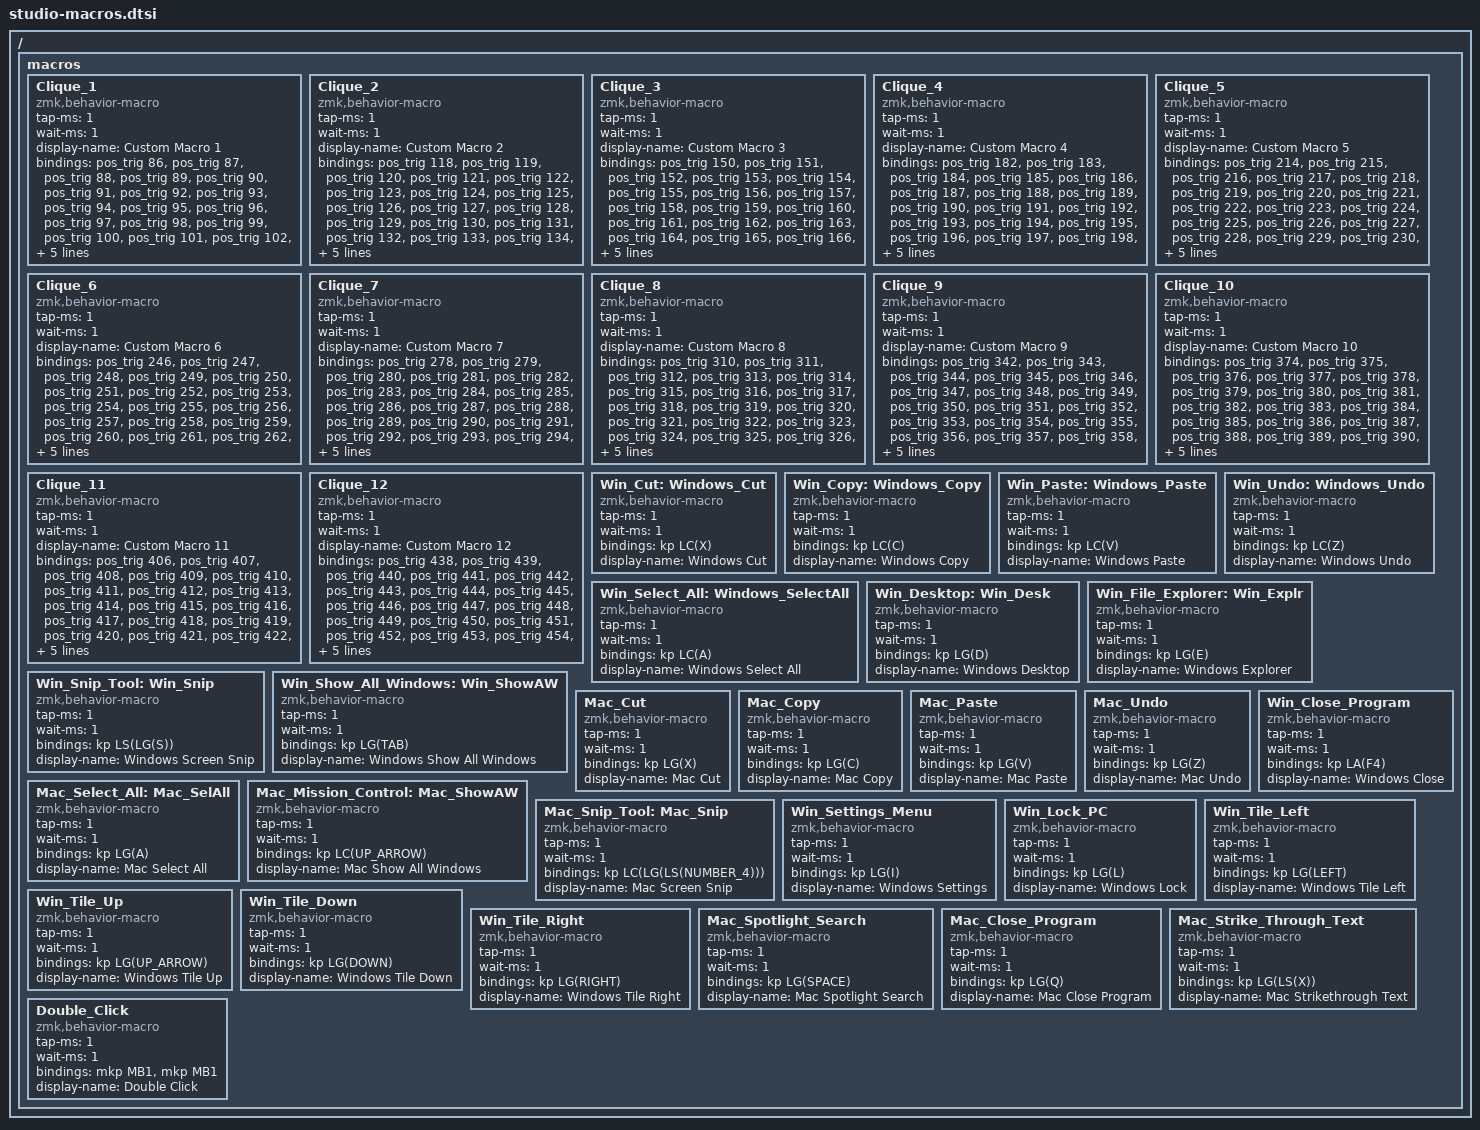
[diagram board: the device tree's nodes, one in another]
#include <dt-bindings/zmk/backlight.h>
#include <dt-bindings/zmk/bt.h>
#include <dt-bindings/zmk/keys.h>
#include <dt-bindings/zmk/pointing.h>
#include <dt-bindings/zmk/outputs.h>
#include <behaviors/position_trigger.dtsi>


/ {
    macros {
        Clique_1: Clique_1{
            compatible = "zmk,behavior-macro";
            #binding-cells = <0>;
            tap-ms = <1>;
            wait-ms = <1>;
            display-name = "Custom Macro 1";
            bindings = <&pos_trig 86 &pos_trig 87 &pos_trig 88 &pos_trig 89 &pos_trig 90 &pos_trig 91 &pos_trig 92 &pos_trig 93 &pos_trig 94 &pos_trig 95 &pos_trig 96 &pos_trig 97 &pos_trig 98 &pos_trig 99 &pos_trig 100 &pos_trig 101 &pos_trig 102 &pos_trig 103 &pos_trig 104 &pos_trig 105 &pos_trig 106 &pos_trig 107 &pos_trig 108 &pos_trig 109 &pos_trig 110 &pos_trig 111 &pos_trig 112 &pos_trig 113 &pos_trig 114 &pos_trig 115 &pos_trig 116 &pos_trig 117 >;
        };
        Clique_2: Clique_2{
            compatible = "zmk,behavior-macro";
            #binding-cells = <0>;
            tap-ms = <1>;
            wait-ms = <1>;
            display-name = "Custom Macro 2";
            bindings = <&pos_trig 118 &pos_trig 119 &pos_trig 120 &pos_trig 121 &pos_trig 122 &pos_trig 123 &pos_trig 124 &pos_trig 125 &pos_trig 126 &pos_trig 127 &pos_trig 128 &pos_trig 129 &pos_trig 130 &pos_trig 131 &pos_trig 132 &pos_trig 133 &pos_trig 134 &pos_trig 135 &pos_trig 136 &pos_trig 137 &pos_trig 138 &pos_trig 139 &pos_trig 140 &pos_trig 141 &pos_trig 142 &pos_trig 143 &pos_trig 144 &pos_trig 145 &pos_trig 146 &pos_trig 147 &pos_trig 148 &pos_trig 149 >;
        };
        Clique_3: Clique_3{
            compatible = "zmk,behavior-macro";
            #binding-cells = <0>;
            tap-ms = <1>;
            wait-ms = <1>;
            display-name = "Custom Macro 3";
            bindings = <&pos_trig 150 &pos_trig 151 &pos_trig 152 &pos_trig 153 &pos_trig 154 &pos_trig 155 &pos_trig 156 &pos_trig 157 &pos_trig 158 &pos_trig 159 &pos_trig 160 &pos_trig 161 &pos_trig 162 &pos_trig 163 &pos_trig 164 &pos_trig 165 &pos_trig 166 &pos_trig 167 &pos_trig 168 &pos_trig 169 &pos_trig 170 &pos_trig 171 &pos_trig 172 &pos_trig 173 &pos_trig 174 &pos_trig 175 &pos_trig 176 &pos_trig 177 &pos_trig 178 &pos_trig 179 &pos_trig 180 &pos_trig 181 >;
        };
        Clique_4: Clique_4{
            compatible = "zmk,behavior-macro";
            #binding-cells = <0>;
            tap-ms = <1>;
            wait-ms = <1>;
            display-name = "Custom Macro 4";
            bindings = <&pos_trig 182 &pos_trig 183 &pos_trig 184 &pos_trig 185 &pos_trig 186 &pos_trig 187 &pos_trig 188 &pos_trig 189 &pos_trig 190 &pos_trig 191 &pos_trig 192 &pos_trig 193 &pos_trig 194 &pos_trig 195 &pos_trig 196 &pos_trig 197 &pos_trig 198 &pos_trig 199 &pos_trig 200 &pos_trig 201 &pos_trig 202 &pos_trig 203 &pos_trig 204 &pos_trig 205 &pos_trig 206 &pos_trig 207 &pos_trig 208 &pos_trig 209 &pos_trig 210 &pos_trig 211 &pos_trig 212 &pos_trig 213 >;
        };
        Clique_5: Clique_5{
            compatible = "zmk,behavior-macro";
            #binding-cells = <0>;
            tap-ms = <1>;
            wait-ms = <1>;
            display-name = "Custom Macro 5";
            bindings = <&pos_trig 214 &pos_trig 215 &pos_trig 216 &pos_trig 217 &pos_trig 218 &pos_trig 219 &pos_trig 220 &pos_trig 221 &pos_trig 222 &pos_trig 223 &pos_trig 224 &pos_trig 225 &pos_trig 226 &pos_trig 227 &pos_trig 228 &pos_trig 229 &pos_trig 230 &pos_trig 231 &pos_trig 232 &pos_trig 233 &pos_trig 234 &pos_trig 235 &pos_trig 236 &pos_trig 237 &pos_trig 238 &pos_trig 239 &pos_trig 240 &pos_trig 241 &pos_trig 242 &pos_trig 243 &pos_trig 244 &pos_trig 245 >;
        };
        Clique_6: Clique_6{
            compatible = "zmk,behavior-macro";
            #binding-cells = <0>;
            tap-ms = <1>;
            wait-ms = <1>;
            display-name = "Custom Macro 6";
            bindings = <&pos_trig 246 &pos_trig 247 &pos_trig 248 &pos_trig 249 &pos_trig 250 &pos_trig 251 &pos_trig 252 &pos_trig 253 &pos_trig 254 &pos_trig 255 &pos_trig 256 &pos_trig 257 &pos_trig 258 &pos_trig 259 &pos_trig 260 &pos_trig 261 &pos_trig 262 &pos_trig 263 &pos_trig 264 &pos_trig 265 &pos_trig 266 &pos_trig 267 &pos_trig 268 &pos_trig 269 &pos_trig 270 &pos_trig 271 &pos_trig 272 &pos_trig 273 &pos_trig 274 &pos_trig 275 &pos_trig 276 &pos_trig 277 >;
        };
        Clique_7: Clique_7{
            compatible = "zmk,behavior-macro";
            #binding-cells = <0>;
            tap-ms = <1>;
            wait-ms = <1>;
            display-name = "Custom Macro 7";
            bindings = <&pos_trig 278 &pos_trig 279 &pos_trig 280 &pos_trig 281 &pos_trig 282 &pos_trig 283 &pos_trig 284 &pos_trig 285 &pos_trig 286 &pos_trig 287 &pos_trig 288 &pos_trig 289 &pos_trig 290 &pos_trig 291 &pos_trig 292 &pos_trig 293 &pos_trig 294 &pos_trig 295 &pos_trig 296 &pos_trig 297 &pos_trig 298 &pos_trig 299 &pos_trig 300 &pos_trig 301 &pos_trig 302 &pos_trig 303 &pos_trig 304 &pos_trig 305 &pos_trig 306 &pos_trig 307 &pos_trig 308 &pos_trig 309 >;
        };
        Clique_8: Clique_8{
            compatible = "zmk,behavior-macro";
            #binding-cells = <0>;
            tap-ms = <1>;
            wait-ms = <1>;
            display-name = "Custom Macro 8";
            bindings = <&pos_trig 310 &pos_trig 311 &pos_trig 312 &pos_trig 313 &pos_trig 314 &pos_trig 315 &pos_trig 316 &pos_trig 317 &pos_trig 318 &pos_trig 319 &pos_trig 320 &pos_trig 321 &pos_trig 322 &pos_trig 323 &pos_trig 324 &pos_trig 325 &pos_trig 326 &pos_trig 327 &pos_trig 328 &pos_trig 329 &pos_trig 330 &pos_trig 331 &pos_trig 332 &pos_trig 333 &pos_trig 334 &pos_trig 335 &pos_trig 336 &pos_trig 337 &pos_trig 338 &pos_trig 339 &pos_trig 340 &pos_trig 341 >;
        };
        Clique_9: Clique_9{
            compatible = "zmk,behavior-macro";
            #binding-cells = <0>;
            tap-ms = <1>;
            wait-ms = <1>;
            display-name = "Custom Macro 9";
            bindings = <&pos_trig 342 &pos_trig 343 &pos_trig 344 &pos_trig 345 &pos_trig 346 &pos_trig 347 &pos_trig 348 &pos_trig 349 &pos_trig 350 &pos_trig 351 &pos_trig 352 &pos_trig 353 &pos_trig 354 &pos_trig 355 &pos_trig 356 &pos_trig 357 &pos_trig 358 &pos_trig 359 &pos_trig 360 &pos_trig 361 &pos_trig 362 &pos_trig 363 &pos_trig 364 &pos_trig 365 &pos_trig 366 &pos_trig 367 &pos_trig 368 &pos_trig 369 &pos_trig 370 &pos_trig 371 &pos_trig 372 &pos_trig 373 >;
        };
        Clique_10: Clique_10{
            compatible = "zmk,behavior-macro";
            #binding-cells = <0>;
            tap-ms = <1>;
            wait-ms = <1>;
            display-name = "Custom Macro 10";
            bindings = <&pos_trig 374 &pos_trig 375 &pos_trig 376 &pos_trig 377 &pos_trig 378 &pos_trig 379 &pos_trig 380 &pos_trig 381 &pos_trig 382 &pos_trig 383 &pos_trig 384 &pos_trig 385 &pos_trig 386 &pos_trig 387 &pos_trig 388 &pos_trig 389 &pos_trig 390 &pos_trig 391 &pos_trig 392 &pos_trig 393 &pos_trig 394 &pos_trig 395 &pos_trig 396 &pos_trig 397 &pos_trig 398 &pos_trig 399 &pos_trig 400 &pos_trig 401 &pos_trig 402 &pos_trig 403 &pos_trig 404 &pos_trig 405 >;
        };
        Clique_11: Clique_11{
            compatible = "zmk,behavior-macro";
            #binding-cells = <0>;
            tap-ms = <1>;
            wait-ms = <1>;
            display-name = "Custom Macro 11";
            bindings = <&pos_trig 406 &pos_trig 407 &pos_trig 408 &pos_trig 409 &pos_trig 410 &pos_trig 411 &pos_trig 412 &pos_trig 413 &pos_trig 414 &pos_trig 415 &pos_trig 416 &pos_trig 417 &pos_trig 418 &pos_trig 419 &pos_trig 420 &pos_trig 421 &pos_trig 422 &pos_trig 423 &pos_trig 424 &pos_trig 425 &pos_trig 426 &pos_trig 427 &pos_trig 428 &pos_trig 429 &pos_trig 430 &pos_trig 431 &pos_trig 432 &pos_trig 433 &pos_trig 434 &pos_trig 435 &pos_trig 436 &pos_trig 437 >;
        };
        Clique_12: Clique_12{
            compatible = "zmk,behavior-macro";
            #binding-cells = <0>;
            tap-ms = <1>;
            wait-ms = <1>;
            display-name = "Custom Macro 12";
            bindings = <&pos_trig 438 &pos_trig 439 &pos_trig 440 &pos_trig 441 &pos_trig 442 &pos_trig 443 &pos_trig 444 &pos_trig 445 &pos_trig 446 &pos_trig 447 &pos_trig 448 &pos_trig 449 &pos_trig 450 &pos_trig 451 &pos_trig 452 &pos_trig 453 &pos_trig 454 &pos_trig 455 &pos_trig 456 &pos_trig 457 &pos_trig 458 &pos_trig 459 &pos_trig 460 &pos_trig 461 &pos_trig 462 &pos_trig 463 &pos_trig 464 &pos_trig 465 &pos_trig 466 &pos_trig 467 &pos_trig 468 &pos_trig 469 >;
        };
        Win_Cut: Windows_Cut {
            compatible = "zmk,behavior-macro";
            #binding-cells = <0>;
            tap-ms = <1>;
            wait-ms = <1>;
            bindings = <&kp LC(X)>;
            display-name = "Windows Cut";
        };

        Win_Copy: Windows_Copy {
            compatible = "zmk,behavior-macro";
            #binding-cells = <0>;
            tap-ms = <1>;
            wait-ms = <1>;
            bindings = <&kp LC(C)>;
            display-name = "Windows Copy";
        };

        Win_Paste: Windows_Paste {
            compatible = "zmk,behavior-macro";
            #binding-cells = <0>;
            tap-ms = <1>;
            wait-ms = <1>;
            bindings = <&kp LC(V)>;
            display-name = "Windows Paste";
        };

        Win_Select_All: Windows_SelectAll {
            compatible = "zmk,behavior-macro";
            #binding-cells = <0>;
            tap-ms = <1>;
            wait-ms = <1>;
            bindings = <&kp LC(A)>;
            display-name = "Windows Select All";
        };

        Win_Undo: Windows_Undo {
            compatible = "zmk,behavior-macro";
            #binding-cells = <0>;
            tap-ms = <1>;
            wait-ms = <1>;
            bindings = <&kp LC(Z)>;
            display-name = "Windows Undo";
        };

        Win_Desktop: Win_Desk {
            compatible = "zmk,behavior-macro";
            #binding-cells = <0>;
            tap-ms = <1>;
            wait-ms = <1>;
            bindings = <&kp LG(D)>;
            display-name = "Windows Desktop";
        };

        Win_File_Explorer: Win_Explr {
            compatible = "zmk,behavior-macro";
            #binding-cells = <0>;
            tap-ms = <1>;
            wait-ms = <1>;
            bindings = <&kp LG(E)>;
            display-name = "Windows Explorer";
        };

        Win_Snip_Tool: Win_Snip {
            compatible = "zmk,behavior-macro";
            #binding-cells = <0>;
            tap-ms = <1>;
            wait-ms = <1>;
            bindings = <&kp LS(LG(S))>;
            display-name = "Windows Screen Snip";
        };

        Win_Show_All_Windows: Win_ShowAW {
            compatible = "zmk,behavior-macro";
            #binding-cells = <0>;
            tap-ms = <1>;
            wait-ms = <1>;
            bindings = <&kp LG(TAB)>;
            display-name = "Windows Show All Windows";
        };

        Mac_Cut: Mac_Cut {
            compatible = "zmk,behavior-macro";
            #binding-cells = <0>;
            tap-ms = <1>;
            wait-ms = <1>;
            bindings = <&kp LG(X)>;
            display-name = "Mac Cut";
        };

        Mac_Copy: Mac_Copy {
            compatible = "zmk,behavior-macro";
            #binding-cells = <0>;
            tap-ms = <1>;
            wait-ms = <1>;
            bindings = <&kp LG(C)>;
            display-name = "Mac Copy";
        };

        Mac_Paste: Mac_Paste {
            compatible = "zmk,behavior-macro";
            #binding-cells = <0>;
            tap-ms = <1>;
            wait-ms = <1>;
            bindings = <&kp LG(V)>;
            display-name = "Mac Paste";
        };

        Mac_Undo: Mac_Undo {
            compatible = "zmk,behavior-macro";
            #binding-cells = <0>;
            tap-ms = <1>;
            wait-ms = <1>;
            bindings = <&kp LG(Z)>;
            display-name = "Mac Undo";
        };

        Mac_Select_All: Mac_SelAll {
            compatible = "zmk,behavior-macro";
            #binding-cells = <0>;
            tap-ms = <1>;
            wait-ms = <1>;
            bindings = <&kp LG(A)>;
            display-name = "Mac Select All";
        };

        Mac_Mission_Control: Mac_ShowAW {
            compatible = "zmk,behavior-macro";
            #binding-cells = <0>;
            tap-ms = <1>;
            wait-ms = <1>;
            bindings = <&kp LC(UP_ARROW)>;
            display-name = "Mac Show All Windows";
        };

        Mac_Snip_Tool: Mac_Snip {
            compatible = "zmk,behavior-macro";
            #binding-cells = <0>;
            tap-ms = <1>;
            wait-ms = <1>;
            bindings = <&kp LC(LG(LS(NUMBER_4)))>;
            display-name = "Mac Screen Snip";
        };

        Win_Close_Program: Win_Close_Program {
            compatible = "zmk,behavior-macro";
            #binding-cells = <0>;
            tap-ms = <1>;
            wait-ms = <1>;
            bindings = <&kp LA(F4)>;
            display-name = "Windows Close";
        };

        Win_Settings_Menu: Win_Settings_Menu {
            compatible = "zmk,behavior-macro";
            #binding-cells = <0>;
            tap-ms = <1>;
            wait-ms = <1>;
            bindings = <&kp LG(I)>;
            display-name = "Windows Settings";
        };

        Win_Lock_PC: Win_Lock_PC {
            compatible = "zmk,behavior-macro";
            #binding-cells = <0>;
            tap-ms = <1>;
            wait-ms = <1>;
            bindings = <&kp LG(L)>;
            display-name = "Windows Lock";
        };

        Win_Tile_Left: Win_Tile_Left {
            compatible = "zmk,behavior-macro";
            #binding-cells = <0>;
            tap-ms = <1>;
            wait-ms = <1>;
            bindings = <&kp LG(LEFT)>;
            display-name = "Windows Tile Left";
        };

        Win_Tile_Up: Win_Tile_Up {
            compatible = "zmk,behavior-macro";
            #binding-cells = <0>;
            tap-ms = <1>;
            wait-ms = <1>;
            bindings = <&kp LG(UP_ARROW)>;
            display-name = "Windows Tile Up";
        };

        Win_Tile_Down: Win_Tile_Down {
            compatible = "zmk,behavior-macro";
            #binding-cells = <0>;
            tap-ms = <1>;
            wait-ms = <1>;
            bindings = <&kp LG(DOWN)>;
            display-name = "Windows Tile Down";
        };

        Win_Tile_Right: Win_Tile_Right {
            compatible = "zmk,behavior-macro";
            #binding-cells = <0>;
            tap-ms = <1>;
            wait-ms = <1>;
            bindings = <&kp LG(RIGHT)>;
            display-name = "Windows Tile Right";
        };

        Mac_Spotlight_Search: Mac_Spotlight_Search {
            compatible = "zmk,behavior-macro";
            #binding-cells = <0>;
            tap-ms = <1>;
            wait-ms = <1>;
            bindings = <&kp LG(SPACE)>;
            display-name = "Mac Spotlight Search";
        };

        Mac_Close_Program: Mac_Close_Program {
            compatible = "zmk,behavior-macro";
            #binding-cells = <0>;
            tap-ms = <1>;
            wait-ms = <1>;
            bindings = <&kp LG(Q)>;
            display-name = "Mac Close Program";
        };

        Mac_Strike_Through_Text: Mac_Strike_Through_Text {
            compatible = "zmk,behavior-macro";
            #binding-cells = <0>;
            tap-ms = <1>;
            wait-ms = <1>;
            bindings = <&kp LG(LS(X))>;
            display-name = "Mac Strikethrough Text";
        };

        Double_Click: Double_Click {
            compatible = "zmk,behavior-macro";
            #binding-cells = <0>;
            tap-ms = <1>;
            wait-ms = <1>;
            bindings = <&mkp MB1 &mkp MB1>;
            display-name = "Double Click";
        };
    };
};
